# PIC32CX5112MTSH128 register map
Vendor: Microchip Technology; Series: PIC32CXMTSH; File version: 0
CPU: CM4 r0p1, little endian, MPU, FPU, 4 interrupt priority bits, 96 interrupts
Registers are 32-bit, read-write, reset 0x0 unless marked. A register's access mark holds for its fields unless they carry their own. Offsets are from the block's base; [hi:lo] are bit positions; {n}, {i} and the like mark numbered series; 'fields as' and 'values as' point back to an identical list.

## SEFC0 — Secure Embedded Flash Controller
Base 0x460E0000; register names take the prefix SEFC_
Same registers: SEFC1 0x460E0200
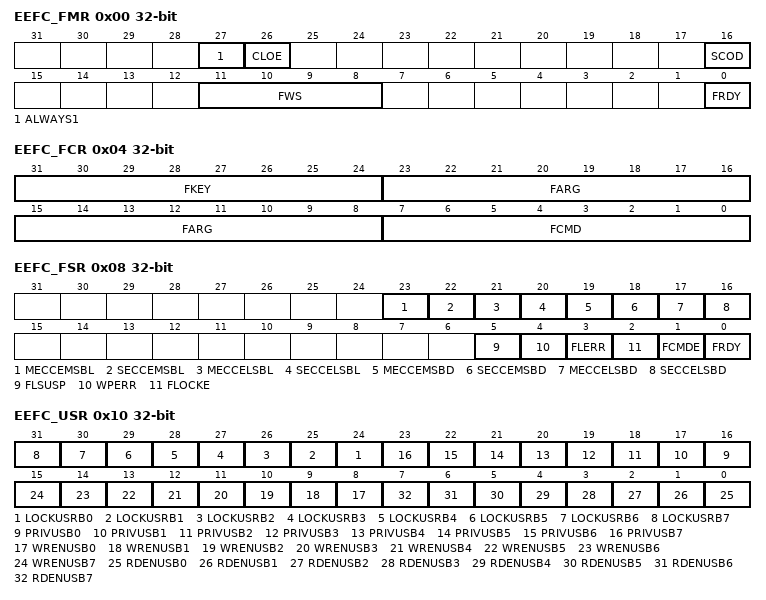
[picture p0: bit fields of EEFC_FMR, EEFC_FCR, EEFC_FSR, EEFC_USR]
0x00 EEFC_FMR — SEFC Flash Mode Register
  [27] ALWAYS1 — Always Written to One
  [26] CLOE — Code Loop Optimization Enable
  [16] SCOD — Sequential Code Optimization Disable
  [11:8] FWS — Flash Wait State
  [0] FRDY — Flash Ready Interrupt Enable
0x04 EEFC_FCR wo — SEFC Flash Command Register
  [31:24] FKEY — Flash Writing Protection Key
    90=PASSWD (The 0x5A value enables the command defined by the bits in the register. If the field is written with a different value, the write is not performed and no action is started.)
  [23:8] FARG — Flash Command Argument
  [7:0] FCMD — Flash Command
    0=GETD (Get Flash descriptor); 1=WP (Write page); 2=WPL (Write page and lock); 7=EPA (Erase pages (8, 16, 32, 64)); 8=SLB (Set lock bit); 9=CLB (Clear lock bit); 10=GLB (Get lock bit); 11=SGPB (Set GPNVM bit); 12=CGPB (Clear GPNVM bit); 13=GGPB (Get GPNVM bit); 14=STUI (Start read unique identifier); 15=SPUI (Stop read unique identifier); 16=GCALB (Get CALIB bit); 17=ES (Erase sector); 18=WUS (Write user signature); 19=EUS (Erase user signature); 20=STUS (Start read user signature); 21=SPUS (Stop read user signature); 23=SUSP (Suspend); 24=RES (Resume); 25=SCK (Send cryptographic key)
0x08 EEFC_FSR ro — SEFC Flash Status Register
  [23] MECCEMSBL — Multiple ECC Error on MSB Part of the Memory Lock Bits
  [22] SECCEMSBL — Single ECC Error on MSB Part of the Memory Lock Bits
  [21] MECCELSBL — Multiple ECC Error on LSB Part of the Memory Lock Bits
  [20] SECCELSBL — Single ECC Error on LSB Part of the Memory Lock Bits
  [19] MECCEMSBD — Multiple ECC Error on MSB Part of the Memory Flash Data Bus (cleared on read)
  [18] SECCEMSBD — Single ECC Error on MSB Part of the Memory Flash Data Bus (cleared on read)
  [17] MECCELSBD — Multiple ECC Error on LSB Part of the Memory Flash Data Bus (cleared on read)
  [16] SECCELSBD — Single ECC Error on LSB Part of the Memory Flash Data Bus (cleared on read)
  [5] FLSUSP — Flash Suspended Status (cleared when resuming the programming operation)
  [4] WPERR — Write Protection Error Status (cleared on read)
  [3] FLERR — Flash Error Status (cleared when a programming operation starts)
  [2] FLOCKE — Flash Lock Error Status (cleared on read or by writing EEFC_FCR)
  [1] FCMDE — Flash Command Error Status (cleared on read)
  [0] FRDY — Flash Ready Status (cleared when Flash is busy)
0x0C EEFC_FRR ro — SEFC Flash Result Register
  [31:0] FVALUE — Flash Result Value
0x10 EEFC_USR — SEFC User Signature Rights Register
  [n+24] LOCKUSRB{n} (n=0..7) — Lock User Signature Rights for User Signature Block {n}
  [n+16] PRIVUSB{n} (n=0..7) — Privileged Access for User Signature Block {n}
  [n+8] WRENUSB{n} (n=0..7) — Write Enable for User Signature Block {n}
  [n] RDENUSB{n} (n=0..7) — Read Enable for User Signature Block {n}
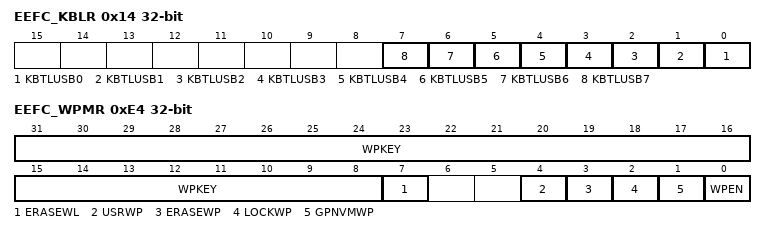
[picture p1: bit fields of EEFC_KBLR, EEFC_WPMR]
0x14 EEFC_KBLR — SEFC Key Bus Lock Register
  [n] KBTLUSB{n} (n=0..7) — Key Bus Transfer Lock from User Signature Block {n}
0xE4 EEFC_WPMR — Write Protection Mode Register
  [31:8] WPKEY — Write Protection Key
    0x454643=PASSWD (Writing any other value in this field aborts the write operation. Always reads as 0.)
  [7] ERASEWL — Erase and Write Lock
  [4] USRWP — User Signature Write Protection
  [3] ERASEWP — Erase and Write Protection
  [2] LOCKWP — Lock Bit Write Protection
  [1] GPNVMWP — GPNVM Bit Write Protection
  [0] WPEN — Write Protection Enable

## SFR — Special Function Register
Base 0x40050400
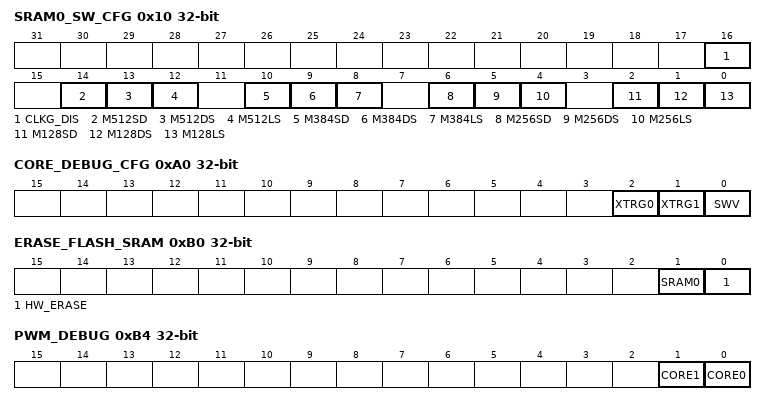
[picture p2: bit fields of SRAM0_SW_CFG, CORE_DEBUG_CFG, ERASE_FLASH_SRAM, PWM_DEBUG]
0x10 SRAM0_SW_CFG — SRAM0 Software Config Register
  [16] CLKG_DIS — Clock Gating Disable
  [14] M512SD — 512 KB Shutdown Mode
  [13] M512DS — 512 KB Deep Sleep Mode
  [12] M512LS — 512 KB Light Sleep Mode
  [10] M384SD — 384 KB Shutdown Mode
  [9] M384DS — 384 KB Deep Sleep Mode
  [8] M384LS — 384 KB Light Sleep Mode
  [6] M256SD — 256 KB Shutdown Mode
  [5] M256DS — 256 KB Deep Sleep Mode
  [4] M256LS — 256 KB Light Sleep Mode
  [2] M128SD — 128 KB Shutdown Mode
  [1] M128DS — 128 KB Deep Sleep Mode
  [0] M128LS — 128 KB Light Sleep Mode
0x70 FLASH — Flash Memory Configuration Register
  [0] PATCH_BYPASS
0x80 OPT_LINK — Optical Link Register
  [0] CLK_SELECT — Clock Selection
0xA0 CORE_DEBUG_CFG — Core Debug Configuration Register
  [2] XTRG0 — From Core 0 to Core 1 Cross Triggering
  [1] XTRG1 — From Core 1 to Core 0 Cross Triggering
  [0] SWV — SWV Selection
0xB0 ERASE_FLASH_SRAM
  [1] SRAM0 — Erase SRAM0 Content
    0=NOT_DELETED (If HW_ERASE = 1, and HW erase signal assertion occurs, SRAM0 content is not deleted.); 1=DELETED (If HW_ERASE = 1, and HW erase signal assertion occurs, SRAM0 content is deleted.)
  [0] HW_ERASE — PB2/Peripherals or Hardware Erase Signal Assignment
    0=DISABLE (Hardware erase signal disabled. PB2 pin can be used in GPIO or Peripheral IO mode.); 1=ENABLE (Hardware erase signal enabled. PB2 pin is assigned to Flash erase function.)
0xB4 PWM_DEBUG
  [1] CORE1 — Debug Information Propagation Mode
    0=NOT_SENT (Core x does not send the debug signal to the PWM.); 1=SENT (Core x sends the debug signal to PWM. Refer to 'Debug Mode' in the section 'Pulse Width Modulation Controller (PWM)' for details on configuring an action when the debug signal is active.)
  [0] CORE0 — Debug Information Propagation Mode
    values as CORE1
0xBC WAIT_MODE — Improved Wait Mode Register
  [0] CONTROL — Improved Wait Mode Control
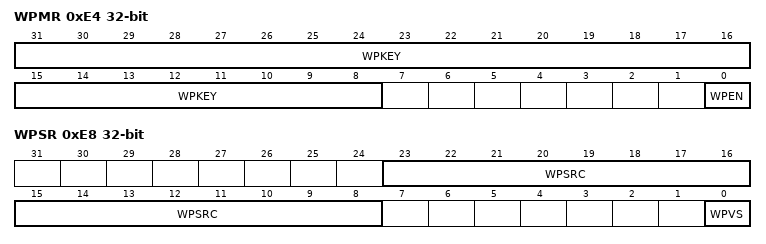
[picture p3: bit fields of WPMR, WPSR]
0xE4 WPMR — Write Protection Mode Register
  [31:8] WPKEY — Write Protection Key
    0x534652=PASSWD (Writing any other value in this field aborts the write operation of the WPEN bit. Always reads as 0.)
  [0] WPEN — Write Protection Enable
0xE8 WPSR — Write Protection Status Register
  [23:8] WPSRC — Write Protection Source
  [0] WPVS — Write Protection Violation Status

## Notices in the file
Copyright (c) 2025 Microchip Technology Inc.
SPDX-License-Identifier: Apache-2.0
Licensed under the Apache License, Version 2.0 (the "License");
you may not use this file except in compliance with the License.
You may obtain a copy of the License at
http://www.apache.org/licenses/LICENSE-2.0
Unless required by applicable law or agreed to in writing, software
distributed under the License is distributed on an "AS IS" BASIS,
WITHOUT WARRANTIES OR CONDITIONS OF ANY KIND, either express or implied.
See the License for the specific language governing permissions and
limitations under the License.
